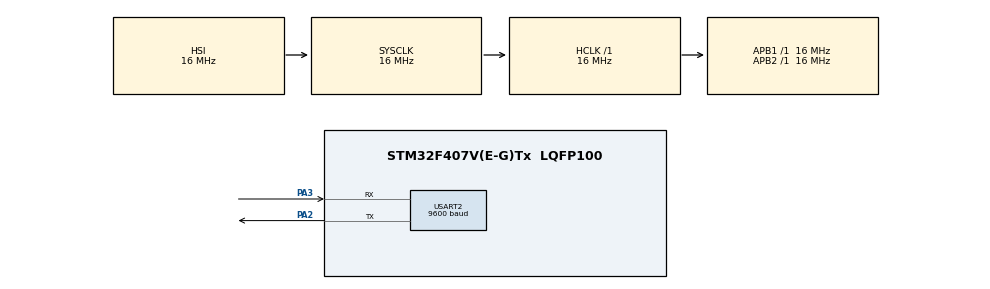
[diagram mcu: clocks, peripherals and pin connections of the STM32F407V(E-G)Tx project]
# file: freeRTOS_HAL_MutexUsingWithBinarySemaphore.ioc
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Mcu.Family=STM32F4
Mcu.Name=STM32F407V(E-G)Tx
Mcu.Package=LQFP100
NVIC.PriorityGroup=NVIC_PRIORITYGROUP_4
NVIC.TIM6_DAC_IRQn=true\:5\:0\:true\:false\:true\:false\:true\:true
NVIC.TimeBase=TIM6_DAC_IRQn
NVIC.TimeBaseIP=TIM6
PA13.Mode=Serial_Wire
PA13.Signal=SYS_JTMS-SWDIO
PA14.Mode=Serial_Wire
PA14.Signal=SYS_JTCK-SWCLK
PA2.Mode=Asynchronous
PA2.Signal=USART2_TX
PA3.Mode=Asynchronous
PA3.Signal=USART2_RX
ProjectManager.HeapSize=0x200
ProjectManager.StackSize=0x400
ProjectManager.TargetToolchain=STM32CubeIDE
RCC.AHBFreq_Value=16000000
RCC.APB1Freq_Value=16000000
RCC.APB2Freq_Value=16000000
RCC.CortexFreq_Value=16000000
RCC.HSE_VALUE=25000000
RCC.HSI_VALUE=16000000
RCC.LSE_VALUE=32768
RCC.SYSCLKFreq_VALUE=16000000
RCC.VCOOutputFreq_Value=192000000
USART2.BaudRate=9600
USART2.VirtualMode=VM_ASYNC
VP_SYS_VS_tim6.Mode=TIM6
board=custom

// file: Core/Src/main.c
/* USER CODE BEGIN Header */
/**
  ******************************************************************************
  * @file           : main.c
  * @brief          : Main program body
  ******************************************************************************
  * @attention
  *
  * Copyright (c) 2022 STMicroelectronics.
  * All rights reserved.
  *
  * This software is licensed under terms that can be found in the LICENSE file
  * in the root directory of this software component.
  * If no LICENSE file comes with this software, it is provided AS-IS.
  *
  ******************************************************************************
  */
/* USER CODE END Header */
#include "main.h"

/* USER CODE BEGIN Includes */
#include "FreeRTOS.h"
#include "task.h"
#include "semphr.h"
#include "string.h"
#include "stdlib.h"
/* USER CODE END Includes */

 UART_HandleTypeDef huart2;

void SystemClock_Config(void);
static void MX_GPIO_Init(void);
static void MX_USART2_UART_Init(void);

/* USER CODE BEGIN 0 */
void Task1_Handler(void *parameters);
void Task2_Handler(void *parameters);
void sendMessage(char *message);
/*************************tasks***********************************************/
TaskHandle_t task1Handler 		= NULL;
TaskHandle_t task2Handler 		= NULL;

///*************************semaphore*******************************************/
SemaphoreHandle_t xSemaphore = NULL;

void sendMessage(char *message)
{
	while(__HAL_UART_GET_FLAG(&huart2,UART_FLAG_TXE) != SET);
	HAL_UART_Transmit (&huart2, &message[0], strlen(message), portMAX_DELAY);
}

void Task1_Handler(void *parameters)
{
	while(1)
	{
		xSemaphoreTake(xSemaphore, portMAX_DELAY);
		sendMessage("Task1: processing task-1. \r\n");
		xSemaphoreGive(xSemaphore);
		vTaskDelay(pdMS_TO_TICKS(500));
	}
}
void Task2_Handler(void *parameters)
{
	while(1)
	{
		xSemaphoreTake(xSemaphore, portMAX_DELAY);
		sendMessage("Task2: processing task-2. \r\n");
		xSemaphoreGive(xSemaphore);
		vTaskDelay(pdMS_TO_TICKS(500));
	}
}

/* USER CODE END 0 */

int main(void)
{

  /* MCU Configuration--------------------------------------------------------*/

  /* Reset of all peripherals, Initializes the Flash interface and the Systick. */
  HAL_Init();

  /* Configure the system clock */
  SystemClock_Config();

  /* Initialize all configured peripherals */
  MX_GPIO_Init();
  MX_USART2_UART_Init();
  /* USER CODE BEGIN 2 */

  sendMessage("Mutex with Binary Semaphore \r\n");

   vSemaphoreCreateBinary(xSemaphore);

  if((xSemaphore != NULL))
  {

	  sendMessage("Semaphore and Tasks are created\r\n");

	  xTaskCreate(Task1_Handler,
				  "Task1",
				  configMINIMAL_STACK_SIZE*3,
				  NULL,
				  2,
				  &task1Handler);

	  xTaskCreate(Task2_Handler,
				  "Task2",
				  configMINIMAL_STACK_SIZE*3,
				  NULL,
				  2,
				  &task2Handler);

	  vTaskStartScheduler();
  }
  else
  {
	  sendMessage("Semaphore and Tasks are not created\r\n");

  }
  /* USER CODE END 2 */

  /* Infinite loop */
  while (1)
  {

  }
}

void SystemClock_Config(void)
{
  RCC_OscInitTypeDef RCC_OscInitStruct = {0};
  RCC_ClkInitTypeDef RCC_ClkInitStruct = {0};

  /** Configure the main internal regulator output voltage
  */
  __HAL_RCC_PWR_CLK_ENABLE();
  __HAL_PWR_VOLTAGESCALING_CONFIG(PWR_REGULATOR_VOLTAGE_SCALE1);

  /** Initializes the RCC Oscillators according to the specified parameters
  * in the RCC_OscInitTypeDef structure.
  */
  RCC_OscInitStruct.OscillatorType = RCC_OSCILLATORTYPE_HSI;
  RCC_OscInitStruct.HSIState = RCC_HSI_ON;
  RCC_OscInitStruct.HSICalibrationValue = RCC_HSICALIBRATION_DEFAULT;
  RCC_OscInitStruct.PLL.PLLState = RCC_PLL_NONE;
  if (HAL_RCC_OscConfig(&RCC_OscInitStruct) != HAL_OK)
  {
    Error_Handler();
  }

  /** Initializes the CPU, AHB and APB buses clocks
  */
  RCC_ClkInitStruct.ClockType = RCC_CLOCKTYPE_HCLK|RCC_CLOCKTYPE_SYSCLK
                              |RCC_CLOCKTYPE_PCLK1|RCC_CLOCKTYPE_PCLK2;
  RCC_ClkInitStruct.SYSCLKSource = RCC_SYSCLKSOURCE_HSI;
  RCC_ClkInitStruct.AHBCLKDivider = RCC_SYSCLK_DIV1;
  RCC_ClkInitStruct.APB1CLKDivider = RCC_HCLK_DIV1;
  RCC_ClkInitStruct.APB2CLKDivider = RCC_HCLK_DIV1;

  if (HAL_RCC_ClockConfig(&RCC_ClkInitStruct, FLASH_LATENCY_0) != HAL_OK)
  {
    Error_Handler();
  }
}

static void MX_USART2_UART_Init(void)
{

  huart2.Instance = USART2;
  huart2.Init.BaudRate = 9600;
  huart2.Init.WordLength = UART_WORDLENGTH_8B;
  huart2.Init.StopBits = UART_STOPBITS_1;
  huart2.Init.Parity = UART_PARITY_NONE;
  huart2.Init.Mode = UART_MODE_TX_RX;
  huart2.Init.HwFlowCtl = UART_HWCONTROL_NONE;
  huart2.Init.OverSampling = UART_OVERSAMPLING_16;
  if (HAL_UART_Init(&huart2) != HAL_OK)
  {
    Error_Handler();
  }

}

static void MX_GPIO_Init(void)
{

  /* GPIO Ports Clock Enable */
  __HAL_RCC_GPIOA_CLK_ENABLE();

}

void HAL_TIM_PeriodElapsedCallback(TIM_HandleTypeDef *htim)
{
  if (htim->Instance == TIM6) {
    HAL_IncTick();
  }
}

void Error_Handler(void)
{
  __disable_irq();
  while (1)
  {
  }
}
